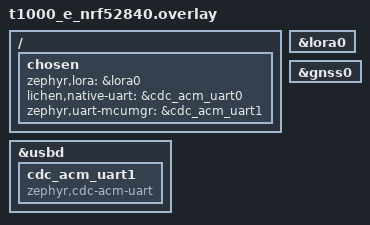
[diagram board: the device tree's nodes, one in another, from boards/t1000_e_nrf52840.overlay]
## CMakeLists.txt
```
# SPDX-License-Identifier: GPL-3.0-or-later
# SPDX-FileCopyrightText: The contributors to the LICHEN project

cmake_minimum_required(VERSION 3.20.0)
include(${CMAKE_CURRENT_LIST_DIR}/../../cmake/lichen_build_epoch.cmake)
lichen_configure_time_build_epoch()
find_package(Zephyr REQUIRED HINTS $ENV{ZEPHYR_BASE})
project(lichen_puck)

target_sources(app PRIVATE src/main.c src/puck_location.c)
target_include_directories(app PRIVATE
  ${CMAKE_CURRENT_SOURCE_DIR}/../../lib/native/include)

zephyr_linker_sources(DATA_SECTIONS sections-ram.ld)
zephyr_iterable_section(
  NAME coap_resource_lichen_coap
  GROUP DATA_REGION ${XIP_ALIGN_WITH_INPUT}
  SUBALIGN CONFIG_LINKER_ITERABLE_SUBALIGN)
# Server section owned exclusively by subsys/lichen/coap/CMakeLists.txt
# under CONFIG_LICHEN_COAP_SERVER_STANDALONE (mutually exclusive with
# modular LICHEN_COAP_CONFIG used by puck/gateway per Kconfig and
# AGENTS.md init graph). Avoids duplication/symbol conflicts from
# worker3 merge.
```

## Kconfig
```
mainmenu "LICHEN Puck"

config LICHEN_PUCK_BEACON_INTERVAL_MS
	int "Beacon TX interval (ms)"
	default 60000
	help
	  How often the puck transmits a bare LICHEN announce beacon.
	  60 s is appropriate for field use; reduce to 5 s for bench testing.

source "Kconfig.zephyr"
```

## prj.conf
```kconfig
# LICHEN puck — field device Kconfig
# Full mesh stack: LoRa radio, IPv6, UDP, CoAP

# LoRa radio (driver selected per-board: LORA_SX12XX or LORA_STM32WL_SUBGHZ_RADIO)
CONFIG_LORA=y

# Networking (disable 802.15.4 L2 — we drive the radio directly)
CONFIG_NET_L2_CUSTOM_IEEE802154=n
CONFIG_NETWORKING=y
CONFIG_NET_IPV6=y
CONFIG_NET_UDP=y
CONFIG_NET_SOCKETS=y

# Application protocols
CONFIG_COAP=y

# LICHEN board capability HAL
CONFIG_LICHEN=y
CONFIG_LICHEN_HAL=y

# RNG (needed for nonces, OSCORE)
CONFIG_ENTROPY_GENERATOR=y
CONFIG_CRC=y

# Stack sizes — LoRa + IPv6 + CoAP need generous stacks.
# Any thread that can originate an L2 TX runs SCHC compression + Monocypher
# Ed25519 signing (2-6 KB of stack) via lichen_link_tx: the zephyr coap_client
# thread (1 KB default — overflowed and wedged both nRF boards at the first
# CoAP send, bd r002) and the system workqueue (ND/DAD-originated sends).
CONFIG_MAIN_STACK_SIZE=4096
CONFIG_SYSTEM_WORKQUEUE_STACK_SIZE=4096
CONFIG_COAP_CLIENT_STACK_SIZE=8192
CONFIG_NET_TX_STACK_SIZE=8192

# Block-wise transfers sized so each block response fits the L2 MTU; must
# match the 128-byte blocks the gateway serves for large resources.
CONFIG_COAP_CLIENT_BLOCK_SIZE=128

# CON retransmit timeout must exceed the real link RTT or the retransmit
# grabs the half-duplex modem exactly when the response is arriving and
# jams it. Worst case at SF10: ~1 s RX window + 0.8 s request airtime +
# ~1 s gateway window + 1.6 s max response airtime ≈ 4.4 s.
# LICHEN uses 15s (matching LICHEN_ACK_TIMEOUT in Python/Rust) to avoid
# premature retransmits over high-latency LoRa links.
CONFIG_COAP_INIT_ACK_TIMEOUT_MS=15000
# RX side of the same: Ed25519 verify + SCHC decompress run on the LoRa L2
# RX thread; IPv6/UDP delivery runs on the net RX thread.
CONFIG_LICHEN_LORA_L2_RX_STACK_SIZE=8192
CONFIG_NET_RX_STACK_SIZE=4096

# Short RX window for TX responsiveness (every TX waits out the in-flight
# window via the modem mutex). Frames that straddle the boundary are safe:
# the drivers hold the window open on preamble/header detection instead of
# aborting mid-reception.
CONFIG_LICHEN_LORA_L2_RX_TIMEOUT_MS=1000

# MbedTLS disabled — OSCORE crypto is provided by the LICHEN crypto layer
CONFIG_MBEDTLS=n

# Safety (spec appendix-c-safety)
CONFIG_STACK_CANARIES=y
CONFIG_STACK_SENTINEL=y
CONFIG_ASSERT=y
CONFIG_ASSERT_VERBOSE=y

# Logging
CONFIG_LOG=y
CONFIG_LOG_DEFAULT_LEVEL=3

# Hardware watchdog — resilience against radio-driver lockups (see main.c).
CONFIG_WATCHDOG=y
```

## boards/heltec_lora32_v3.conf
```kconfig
# Heltec LoRa32 v3 board config — USB CDC-ACM + SLIP
# ESP32-S3 uses Zephyr's USB device stack next (UDC)

CONFIG_USB_DEVICE_STACK_NEXT=y
CONFIG_UDC_ESP32SX=y
CONFIG_USBD_CDC_ACM_CLASS=y

CONFIG_SLIP=y
CONFIG_NET_L2_SLIP=y
CONFIG_UART_LINE_CTRL=y
CONFIG_NET_BUF_DATA_SIZE=128
```

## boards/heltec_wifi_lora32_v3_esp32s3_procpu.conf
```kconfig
# SPDX-License-Identifier: GPL-3.0-or-later
# SPDX-FileCopyrightText: The contributors to the LICHEN project
#
# Heltec WiFi LoRa 32 V3 puck config — ESP32-S3 + SX1262.
CONFIG_LORA_SX126X=y
CONFIG_LICHEN_HAS_LORA=y
CONFIG_LICHEN_RADIO_MODEL_SX126X=y
CONFIG_LICHEN_COAP=y
CONFIG_LICHEN_LORA_L2=y
CONFIG_LICHEN_L2=y
# lichen_coap_request() k_malloc()s per-request state.
CONFIG_HEAP_MEM_POOL_SIZE=4096
# 5 s beacon for bench testing (default 60 s) — matches the nRF pucks.
CONFIG_LICHEN_PUCK_BEACON_INTERVAL_MS=5000

# L2 + CoAP path (board-level addition to prj.conf). Radio arbitration by LICHEN_L2 mutex + TDMA per spec/02a-coordinated-capacity.md §2a.2;
# TINYCRYPT auto-pulled via LICHEN_L2 select.
# Battery support for real hardware test (N30 1100mAh) — voltage-divider
# on GPIO1/ADC1_CH0 with GPIO37 control pin (see board DTS + Meshtastic).
CONFIG_LICHEN_HAS_BATTERY=y
CONFIG_SENSOR=y
CONFIG_ADC=y
CONFIG_LICHEN_L2_DEV_PROVISIONING=y
CONFIG_LICHEN_L2_DEV_PEER_EUI64="7a7ff09dc86c2c10,ee452f74419cf281"
```

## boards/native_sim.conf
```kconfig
CONFIG_LORA_LOOPBACK=y
CONFIG_LICHEN_HAS_LORA=y
CONFIG_LICHEN_RADIO_MODEL_LOOPBACK=y
CONFIG_LICHEN_COAP=y
CONFIG_HEAP_MEM_POOL_SIZE=2048
CONFIG_NET_TC_TX_COUNT=1
CONFIG_NET_TC_THREAD_PREEMPTIVE=y
CONFIG_LICHEN_L2_DEV_PROVISIONING=y
CONFIG_LICHEN_L2_DEV_PEER_EUI64="ee452f74419cf281"
```

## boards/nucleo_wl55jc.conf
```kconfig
# Nucleo-WL55JC (STM32WL55) — built-in Sub-GHz radio, no USB peripheral.
# Memory targets: <50KB RAM, <220KB flash (sw3).

# STM32WL uses the built-in SubGHz radio driver (auto-selected from DTS).
# Explicitly enable it; the SX12xx external driver is not present on this board.
CONFIG_SPI=y
CONFIG_LORA_STM32WL_SUBGHZ_RADIO=y
CONFIG_LICHEN_HAS_LORA=y
CONFIG_LICHEN_COAP=y
CONFIG_IWDG_STM32_INITIAL_TIMEOUT=4000

# No USB hardware on STM32WL55 → no CDC-ACM, no USB stack.
CONFIG_USB_DEVICE_STACK=n
CONFIG_USB_DEVICE_STACK_NEXT=n

# Reduce network buffer counts to fit in 64KB SRAM.
CONFIG_NET_PKT_RX_COUNT=4
CONFIG_NET_PKT_TX_COUNT=4
CONFIG_NET_BUF_RX_COUNT=8
CONFIG_NET_BUF_TX_COUNT=8
CONFIG_NET_BUF_DATA_SIZE=128
CONFIG_NET_IPV6_MAX_NEIGHBORS=4
CONFIG_NET_MAX_CONTEXTS=4

# Reduce thread stack sizes
CONFIG_MAIN_STACK_SIZE=2048
CONFIG_SYSTEM_WORKQUEUE_STACK_SIZE=1024

# Minimal logging (level 1 = errors only) to reduce RAM and flash
CONFIG_LOG_DEFAULT_LEVEL=1
```

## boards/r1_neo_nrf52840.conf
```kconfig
# Muzi Works R1 Neo puck config - nRF52840 + SX1262

CONFIG_LORA_SX126X=y
CONFIG_LICHEN_HAS_LORA=y
CONFIG_LICHEN_RADIO_MODEL_SX126X=y

# LICHEN Native protocol over USB CDC-ACM.
CONFIG_USB_DEVICE_VID=0x239A
CONFIG_USB_DEVICE_PID=0x0029
CONFIG_USB_DEVICE_PRODUCT="LICHEN Puck"
CONFIG_USB_DEVICE_MANUFACTURER="LICHEN"
CONFIG_ZCBOR=y
CONFIG_LICHEN_NATIVE=y
CONFIG_LICHEN_HAS_SERIAL_LOCAL=y

# Board capability boundary for app-facing hardware decisions.
CONFIG_LICHEN_BOARD_NAME="Muzi Works R1 Neo"
CONFIG_LICHEN_HAS_BUTTONS=y
CONFIG_LICHEN_HAS_LEDS=y
CONFIG_LICHEN_UI_PROFILE_TRACKER=y

# R1 Neo battery ADC is modeled in the board DTS as a voltage-divider sensor.
CONFIG_SENSOR=y
CONFIG_LICHEN_HAS_BATTERY=y

# Hardware present but intentionally disabled until validated or modeled.
CONFIG_LICHEN_HAS_DISPLAY=n
CONFIG_LICHEN_HAS_GNSS=n
CONFIG_LICHEN_HAS_PMIC=n
CONFIG_LICHEN_HAS_EXTERNAL_FLASH=n
```

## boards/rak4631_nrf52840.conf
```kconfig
# RAK4631 board config — USB CDC-ACM + SLIP for border-router tethering

CONFIG_LICHEN_BOARD_NAME="RAKwireless RAK4631"

# USB device stack (nRF52840 native USB)
CONFIG_USB_DEVICE_STACK=y
CONFIG_USB_DEVICE_VID=0x239A
CONFIG_USB_DEVICE_PID=0x0029
CONFIG_USB_DEVICE_PRODUCT="LICHEN Puck"
CONFIG_USB_DEVICE_MANUFACTURER="LICHEN"
CONFIG_USB_CDC_ACM=y
CONFIG_UART_LINE_CTRL=y

# LICHEN LCI SLIP over the CDC-ACM virtual serial port
CONFIG_NET_DRIVERS=y
CONFIG_NET_L2_DUMMY=y
CONFIG_SLIP=n
CONFIG_LICHEN_SLIP_TRANSPORT=y
CONFIG_SLIP_TRANSPORT_USB_CDC_ACM=y

# Networking (already in prj.conf; repeated here to be explicit)
CONFIG_NET_IPV6=y

# Larger slip receive buffer (MTU 1280 for IPv6 minimum)
CONFIG_NET_BUF_DATA_SIZE=128

CONFIG_SPI=y
CONFIG_LORA_SX126X=y
CONFIG_LICHEN_HAS_LORA=y
CONFIG_LICHEN_RADIO_MODEL_SX126X=y
CONFIG_LICHEN_HAS_SERIAL_LOCAL=y

# L2/CoAP mode: with a LoRa radio present, LICHEN_LORA_L2/LICHEN_L2 default
# on and main.c compiles the CoAP client path, so LICHEN_COAP must be
# enabled (same as T-Echo). lichen_coap_request() k_malloc()s per-request.
CONFIG_LICHEN_COAP=y
CONFIG_HEAP_MEM_POOL_SIZE=2048

# L2/CoAP dev provisioning to reach CoAP GET /status (fixes startup stall)
# Matches T-Echo/t1000e pattern for bench interoperability with Heltec gateway.

CONFIG_LICHEN_L2_DEV_PROVISIONING=y
CONFIG_LICHEN_L2_DEV_PEER_EUI64="ee452f74419cf281"
```

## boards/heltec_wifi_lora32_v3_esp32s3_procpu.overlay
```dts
/*
 * Heltec WiFi LoRa 32 V3 puck overlay — ESP32-S3 + SX1262
 *
 * The out-of-tree board DTS (lichen/boards/heltec/heltec_wifi_lora32_v3/)
 * already defines lora0 on spi2.  This overlay wires it into the Zephyr
 * LoRa subsystem via the chosen binding.
 */

/ {
	chosen {
		zephyr,lora = &lora0;
	};
};
```

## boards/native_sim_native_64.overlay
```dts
/ {
	chosen {
		zephyr,lora = &lora_loopback;
	};

	lora_loopback: lora {
		compatible = "lichen,lora-loopback";
		status = "okay";
	};
};
```

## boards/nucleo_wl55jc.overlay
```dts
/*
 * Nucleo-WL55JC — STM32WL55 with built-in Sub-GHz radio.
 *
 * The board DTS already configures the Sub-GHz radio (&lora / radio@0 inside
 * &subghzspi) with GPIOs, TCXO timing, and the RFO-HP output. This overlay
 * just points the Zephyr LoRa and SLIP aliases at those nodes.
 *
 * SLIP is tunnelled over LPUART1 (PA2/PA3 → ST-LINK virtual COM port).
 */

/ {
	chosen {
		zephyr,lora      = &lora;
		zephyr,uart-pipe = &lpuart1;
	};
};
```

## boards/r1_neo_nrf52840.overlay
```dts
/*
 * Muzi Works R1 Neo puck overlay - enables SX1262 for the puck app.
 */

/ {
	chosen {
		zephyr,lora = &lora0;
		lichen,native-uart = &cdc_acm_uart0;
	};
};

&lora0 {
	status = "okay";
};
```

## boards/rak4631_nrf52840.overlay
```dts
/*
 * RAK4631 — nRF52840 + SX1262
 *
 * The upstream board definition declares the SX1262 as node label &lora on
 * SPI1 and aliases it as lora0.  This overlay enables the node; runtime RF
 * parameters are set through lora_config().
 */

/ {
	chosen {
		zephyr,lora      = &lora;
		lichen,slip-uart = &cdc_acm_uart0;
	};
};

/* CDC-ACM virtual UART — the host sees this as a /dev/ttyACMx port.
 * The SLIP driver uses it as its serial backend. */
&zephyr_udc0 {
	cdc_acm_uart0: cdc_acm_uart0 {
		compatible = "zephyr,cdc-acm-uart";
	};
};

&lora {
	status = "okay";
};
```

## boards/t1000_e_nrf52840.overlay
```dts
/ {
	chosen {
		zephyr,lora        = &lora0;
		lichen,native-uart = &cdc_acm_uart0;
		zephyr,uart-mcumgr = &cdc_acm_uart1;
	};
};

&lora0  { status = "okay"; };
&gnss0  { status = "okay"; };

/* Second CDC-ACM instance for SMP image management (mcumgr CLI). */
&usbd {
	cdc_acm_uart1: cdc_acm_uart1 {
		compatible = "zephyr,cdc-acm-uart";
	};
};
```

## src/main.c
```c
/* SPDX-License-Identifier: GPL-3.0-or-later */
/* SPDX-FileCopyrightText: The contributors to the LICHEN project */

#include <errno.h>
#include <string.h>

#include <zephyr/device.h>
#include <zephyr/drivers/lora.h>
#include <zephyr/drivers/watchdog.h>
#include <zephyr/kernel.h>
#include <zephyr/pm/device.h>
#include <zephyr/logging/log.h>
#if IS_ENABLED(CONFIG_USB_DEVICE_STACK)
#include <zephyr/usb/usb_device.h>
#endif

#include <lichen/hal.h>

#if IS_ENABLED(CONFIG_LICHEN_NATIVE)
#include <lichen/native.h>
#endif

#include "puck_location.h"

#if IS_ENABLED(CONFIG_LICHEN_L2)
#include <zephyr/net/net_if.h>
#include <zephyr/net/socket.h>
#include <lichen/coap_client.h>
#if IS_ENABLED(CONFIG_LICHEN_COAP_SERVER_STANDALONE)
#include <lichen/coap_server.h>
#endif
#include "lichen_l2.h"
#include "ipv6_addr.h"
#endif

/* Stall-marker uses the nRF GPREGRET2 retention register (nRF boards only). */
#if defined(CONFIG_SOC_FAMILY_NORDIC_NRF)
#include <nrfx_power.h>
#define STALL_MARKER_HAVE 1
#endif

LOG_MODULE_REGISTER(lichen_puck, LOG_LEVEL_INF);

#if IS_ENABLED(CONFIG_LICHEN_L2) && IS_ENABLED(CONFIG_STATS)
#include <zephyr/stats/stats.h>

/* CoAP round-trip counters exported as the "coap" stats group. */
STATS_SECT_START(lichen_coap_stats)
STATS_SECT_ENTRY32(sent)
STATS_SECT_ENTRY32(ok)
STATS_SECT_ENTRY32(err)
STATS_SECT_END;

STATS_NAME_START(lichen_coap_stats)
STATS_NAME(lichen_coap_stats, sent)
STATS_NAME(lichen_coap_stats, ok)
STATS_NAME(lichen_coap_stats, err)
STATS_NAME_END(lichen_coap_stats);

STATS_SECT_DECL(lichen_coap_stats) lichen_coap_stats;
#define COAP_STAT_INC(field) STATS_INC(lichen_coap_stats, field)
#else
#define COAP_STAT_INC(field) do { } while (0)
#endif

/* LoRa parameters per LICHEN spec: SF10 / 125 kHz / CR4-5 @ 915 MHz (US915). */
#define LORA_FREQ_HZ       915000000U
#define LORA_MAX_FRAME     255
#define BEACON_INTERVAL_MS CONFIG_LICHEN_PUCK_BEACON_INTERVAL_MS

/*
 * Unsigned LICHEN announce frame.
 *   [0] length = 4   (bytes following the length field)
 *   [1] llsec  = 0x00  (AddrMode=0, no sig, no enc)
 *   [2] epoch  = 0
 *   [3] seqhi  = 0
 *   [4] seqlo  = incremented on each TX
 */
#define BEACON_HDR_LEN 5
static uint8_t s_beacon[BEACON_HDR_LEN];
static uint8_t s_seqnum;
static uint8_t s_epoch;

#if IS_ENABLED(CONFIG_LICHEN_NATIVE)
/* Placeholder IID — in production derive from nRF52840 FICR. */
static const uint8_t s_iid[8] = { 0x00, 0x11, 0x22, 0x33, 0x44, 0x55, 0x66, 0x77 };

/* Radio stats forwarded to native protocol */
static struct ln_radio_stats s_radio_stats;

#endif

/* --------------------------------------------------------------------------
 * GNSS callback (called from GNSS driver context)
 * -------------------------------------------------------------------------- */

#if defined(LICHEN_HAL_GNSS_DEVICE)
#include <zephyr/drivers/gnss.h>

static void on_gnss_data(const struct device *dev, const struct gnss_data *data)
{
	lichen_puck_location_gnss_callback_for_test(dev, data);
}

GNSS_DATA_CALLBACK_DEFINE(LICHEN_HAL_GNSS_DEVICE, on_gnss_data);
#endif

/* --------------------------------------------------------------------------
 * LICHEN Native incoming message handler
 * -------------------------------------------------------------------------- */

#if IS_ENABLED(CONFIG_LICHEN_NATIVE)
static void on_native_rx(uint8_t msg_type, const uint8_t *buf, size_t len)
{
	/*
	 * lichen_native_handle_rx handles hello and log_subscribe internally.
	 * send_message (0x20) → transmit on LoRa.
	 */
	if (msg_type == LN_TYPE_SEND_MESSAGE) {
		/* Minimal: ignore routing, blast the payload over LoRa.
		 * Full implementation would parse dest IID and route. */
		LOG_DBG("host send_message — LoRa TX not yet implemented");
	} else {
		lichen_native_handle_rx(msg_type, buf, len);
	}
}
#endif

/* --------------------------------------------------------------------------
 * LoRa helpers (raw-radio mode only — under CONFIG_LICHEN_L2 the net
 * interface owns the half-duplex radio and these would fight its RX thread)
 * -------------------------------------------------------------------------- */

#if !IS_ENABLED(CONFIG_LICHEN_L2)
static int lora_set_mode(const struct device *dev, bool tx)
{
	struct lora_modem_config cfg = {
		.frequency     = LORA_FREQ_HZ,
		.bandwidth     = BW_125_KHZ,
		.datarate      = SF_10,
		.coding_rate   = CR_4_5,
		.preamble_len  = 8,
		.tx_power      = 14,
		.tx            = tx,
		.public_network = false,
	};
	return lora_config(dev, &cfg);
}
#endif /* !CONFIG_LICHEN_L2 */

/* Main-loop phase marker (retained across watchdog reset — see stall_report).
 *
 * Stored in the GPREGRET2 retention register, NOT RAM: MCUboot runs between the
 * watchdog reset and the app and clobbers .noinit RAM, but leaves GPREGRET2
 * alone. GPREGRET (reg 0) is reserved for the DFU-touch magic. High nibble
 * 0xA0 = valid marker, low nibble = phase. */
enum stall_phase {
	PH_BOOT = 0, PH_RECV, PH_RX_FORWARD, PH_CFG_TX,
	PH_TX, PH_CFG_RX, PH_NODE_INFO, PH_NPHASES,
};

#define STALL_GPREG_MAGIC 0xA0u

static inline void set_phase(enum stall_phase ph)
{
#if defined(STALL_MARKER_HAVE)
	NRF_POWER->GPREGRET2 = STALL_GPREG_MAGIC | ((uint32_t)ph & 0x0Fu);
#else
	ARG_UNUSED(ph);
#endif
}

#if !IS_ENABLED(CONFIG_LICHEN_L2)
static void send_beacon(const struct device *dev)
{
	/* Build beacon header */
	s_beacon[0] = BEACON_HDR_LEN - 1;
	s_beacon[1] = 0x00;  /* LLSec: AddrMode=0, no sig, no enc */
	if (++s_seqnum == 0) {
		s_epoch++;  /* Increment epoch on seqnum wrap */
	}
	s_beacon[2] = s_epoch;   /* epoch */
	s_beacon[3] = 0x00;      /* seqhi */
	s_beacon[4] = s_seqnum;  /* seqlo */

	set_phase(PH_CFG_TX);
	if (lora_set_mode(dev, true) < 0) {
		LOG_ERR("TX config failed");
		return;
	}
	set_phase(PH_TX);
	int ret = lora_send(dev, s_beacon, sizeof(s_beacon));
	if (ret < 0) {
		LOG_ERR("beacon TX failed: %d", ret);
	} else {
		LOG_INF("beacon seq=%u", s_seqnum);
#if IS_ENABLED(CONFIG_LICHEN_NATIVE)
		s_radio_stats.tx_pkts++;
#endif
	}
	set_phase(PH_CFG_RX);
	lora_set_mode(dev, false);
}
#endif /* !CONFIG_LICHEN_L2 */

#if IS_ENABLED(CONFIG_LICHEN_L2)
static void on_coap_response(void *user_data, int status, uint8_t code,
			     const uint8_t *payload, size_t payload_len)
{
	ARG_UNUSED(user_data);

	if (status != LICHEN_COAP_OK) {
		LOG_WRN("CoAP response error: %d", status);
		COAP_STAT_INC(err);
		return;
	}
	COAP_STAT_INC(ok);
	LOG_INF("CoAP %u.%02u response, %u B payload",
		code >> 5, code & 0x1F, (unsigned int)payload_len);
	if (payload_len > 0) {
		LOG_HEXDUMP_INF(payload, MIN(payload_len, 64), "payload");
	}
}
#endif /* CONFIG_LICHEN_L2 */

/* --------------------------------------------------------------------------
 * Hardware watchdog — resilience against radio-driver lockups
 *
 * A LoRa TX/RX can wedge the main thread (e.g. a radio SPI transaction that
 * never completes when USB-CDC EasyDMA contends with the SPIM). We can't feed
 * the watchdog straight from the main loop: a normal RX wait blocks up to 5 s,
 * so a main-loop-granular watchdog needs a ~20 s timeout — slow recovery that
 * makes host monitoring painful (long USB drop-outs).
 *
 * Instead we track a "progress" heartbeat that the radio driver bumps from
 * inside its poll loops (via the weak lichen_radio_progress() hook it calls),
 * plus the main loop each iteration. A k_timer feeds the SoC watchdog only
 * while the heartbeat is fresh. Normal multi-second RX/TX waits keep bumping
 * the heartbeat so they don't trip it; a genuine stall stops the bumps and the
 * watchdog resets within a few seconds.
 *
 * The feeder runs from a k_timer (system-clock ISR), NOT a thread: under heavy
 * USB-CDC contention the CDC work queue can starve a cooperative feeder thread,
 * which would withhold the feed and reset the SoC even though main is fine. A
 * timer ISR cannot be starved by threads.
 * -------------------------------------------------------------------------- */

/* WDT_STALL_MS must exceed the longest legitimately-blocking main-loop step
 * that does NOT bump the heartbeat — i.e. the SX126x RX k_poll wait (the LR1110
 * RX/TX poll loops bump continuously). We cap the RX window at RX_WINDOW_MS
 * (< WDT_STALL_MS) so a normal RX never looks like a stall. */
#define WDT_TIMEOUT_MS   4000   /* SoC reset if not fed for this long */
#define WDT_STALL_MS     4000   /* feeder withholds the feed after no progress this long */
#define WDT_FEED_MS      500    /* feeder cadence */
#define RX_WINDOW_MS     2000   /* per-iteration RX listen window */

static const struct device *s_wdt;
static int s_wdt_channel = -1;
static atomic_t s_last_progress_ms;

/* Marks forward progress. Strong definition overriding the radio driver's weak
 * stub, so the driver's poll loops bump this heartbeat too. */
void lichen_radio_progress(void)
{
	atomic_set(&s_last_progress_ms, (atomic_val_t)k_uptime_get());
}

/* Runs in system-clock ISR context — feed only while progress is fresh. */
static void wdt_feed_timer_fn(struct k_timer *t)
{
	ARG_UNUSED(t);
	int64_t age = k_uptime_get() - (int64_t)atomic_get(&s_last_progress_ms);

	if (s_wdt && age < WDT_STALL_MS) {
		wdt_feed(s_wdt, s_wdt_channel);
	}
	/* else: no forward progress → withhold feed → SoC resets */
}

static K_TIMER_DEFINE(s_wdt_timer, wdt_feed_timer_fn, NULL);

static void wdt_init(void)
{
	lichen_radio_progress(); /* seed a fresh heartbeat before arming */

#if !DT_NODE_HAS_STATUS(DT_ALIAS(watchdog0), okay)
	/* No watchdog on this board (e.g. native_sim) */
	LOG_WRN("no watchdog0 alias — running without watchdog");
	return;
#else
	s_wdt = DEVICE_DT_GET(DT_ALIAS(watchdog0));
	if (!device_is_ready(s_wdt)) {
		LOG_WRN("watchdog not ready — running without it");
		s_wdt = NULL;
		return;
	}

	struct wdt_timeout_cfg cfg = {
		.flags   = WDT_FLAG_RESET_SOC,
		.window  = { .min = 0, .max = WDT_TIMEOUT_MS },
		.callback = NULL,
	};

	s_wdt_channel = wdt_install_timeout(s_wdt, &cfg);
	if (s_wdt_channel < 0) {
		LOG_WRN("wdt_install_timeout failed: %d", s_wdt_channel);
		s_wdt = NULL;
		return;
	}

	if (wdt_setup(s_wdt, WDT_OPT_PAUSE_HALTED_BY_DBG) < 0) {
		LOG_WRN("wdt_setup failed");
		s_wdt = NULL;
		return;
	}

	k_timer_start(&s_wdt_timer, K_MSEC(WDT_FEED_MS), K_MSEC(WDT_FEED_MS));
	LOG_INF("watchdog armed (%d ms, stall %d ms, timer-fed)",
		WDT_TIMEOUT_MS, WDT_STALL_MS);
#endif /* DT_NODE_HAS_STATUS(DT_ALIAS(watchdog0), okay) */
}

static inline void wdt_kick(void)
{
	lichen_radio_progress();
}

/* --------------------------------------------------------------------------
 * Stall marker — retained across a warm (watchdog) reset
 *
 * The heartbeat watchdog resets the SoC when main stalls, but the deferred log
 * that would say *where* is lost in the reset. set_phase() records the current
 * main-loop phase in a .noinit variable (RAM survives a watchdog reset on
 * nRF52); stall_report() prints it on the next boot. (Types/setter are defined
 * earlier, before send_beacon, since it uses them.)
 * -------------------------------------------------------------------------- */

static void stall_report(void)
{
#if defined(STALL_MARKER_HAVE)
	static const char *const names[PH_NPHASES] = {
		"boot", "recv", "rx_forward", "cfg_tx",
		"tx", "cfg_rx", "node_info",
	};
	uint32_t g  = NRF_POWER->GPREGRET2;
	uint32_t rr = NRF_POWER->RESETREAS;

	NRF_POWER->RESETREAS = rr; /* write-1-to-clear so next boot is fresh */

	uint32_t ph = g & 0x0Fu;
	const char *phn = ((g & 0xF0u) == STALL_GPREG_MAGIC) && ph < PH_NPHASES
			  ? names[ph] : "n/a";

	/* RESETREAS: bit1=DOG(watchdog) bit2=SREQ(soft) bit0=pin bit3=lockup */
	LOG_WRN("*** boot: RESETREAS=0x%08x %s GPREGRET2=0x%02x phase=%s ***",
		rr,
		(rr & BIT(1)) ? "WATCHDOG" :
		(rr & BIT(2)) ? "soft" :
		(rr & BIT(3)) ? "LOCKUP" :
		(rr & BIT(0)) ? "pin" : "poweron/other",
		g, phn);
	set_phase(PH_BOOT);
#endif
}

/* --------------------------------------------------------------------------
 * Main
 * -------------------------------------------------------------------------- */

int main(void)
{
	struct lichen_hal_identity identity;
	int ret;

	LOG_INF("LICHEN puck starting");
	stall_report();

#if IS_ENABLED(CONFIG_LICHEN_L2)
	/* Quiesce the radio before USB bring-up. The L2 RX thread polls the
	 * radio over SPI (EasyDMA) continuously from NET_DEVICE_INIT — on
	 * nRF52840 that traffic during USBD enumeration wedges USB into a
	 * permanent -110 descriptor-read loop (both USB stacks, both radios;
	 * bd lora_ipv6_mesh-r002). Brought back up after USB settles below. */
	struct net_if *l2_iface =
		net_if_get_first_by_type(&NET_L2_GET_NAME(lichen_l2));

	if (l2_iface != NULL) {
		net_if_down(l2_iface);
	}
#endif

	/* Enable USB early so CDC-ACM enumerates before peripheral drivers
	 * start — guarantees serial log visibility even if LoRa/GNSS fails. */
#if IS_ENABLED(CONFIG_USB_DEVICE_STACK)
	usb_enable(NULL);
	k_sleep(K_MSEC(200));
#endif

	lichen_hal_identity_get(&identity);

#if !IS_ENABLED(CONFIG_LICHEN_L2)
	const struct device *lora_dev;

	/* LoRa radio (via the board-capability HAL) */
	ret = lichen_hal_lora_device_get(&lora_dev);
	if (ret < 0) {
		LOG_ERR("LoRa radio unavailable: %d", ret);
		return ret;
	}
	if (lora_set_mode(lora_dev, false) < 0) {
		LOG_ERR("LoRa config failed — spinning for serial debug");
		while (1) {
			wdt_kick();
			k_sleep(K_SECONDS(1));
		}
	}
	LOG_INF("LoRa SF10/125kHz/CR4-5 @ %u Hz", LORA_FREQ_HZ);
#endif

	/* GNSS power-on (PM_DEVICE start) */
#if IS_ENABLED(CONFIG_LICHEN_HAS_GNSS)
	const struct device *gnss_dev;

	if (lichen_hal_gnss_device_get(&gnss_dev) == 0) {
		pm_device_action_run(gnss_dev, PM_DEVICE_ACTION_RESUME);
	}
#endif

	/* LICHEN Native over USB CDC-ACM */
#if IS_ENABLED(CONFIG_LICHEN_NATIVE)
	if (lichen_native_init(on_native_rx) == 0) {
		LOG_INF("LICHEN Native ready");
		lichen_native_send_hello();
	}
#endif

	/* Arm the watchdog just before entering the loop: everything above runs
	 * quickly and deterministically; the loop is where a radio call can
	 * wedge. */
	wdt_init();

#if IS_ENABLED(CONFIG_LICHEN_L2)
	/* L2/CoAP mode: the LICHEN net interface owns the radio and delivers
	 * IPv6 both ways; the app talks CoAP to the dev-provisioned peer.
	 * The ~230 B /status payload arrives via CoAP Block2 (RFC 7959) —
	 * the gateway slices it into 64-byte blocks that each fit the L2
	 * MTU, and the CoAP client reassembles. */
	static const char *const req_path[] = { "status", NULL };
	uint8_t peer_eui64[LICHEN_L2_ADDR_LEN];
	uint8_t peer_iid[LICHEN_L2_ADDR_LEN];
	struct sockaddr_in6 peer_addr = {
		.sin6_family = AF_INET6,
		.sin6_port = htons(5683),
	};
	LOG_INF("L2/CoAP mode on %s", identity.board_name);

	if (l2_iface == NULL) {
		LOG_ERR("no LICHEN L2 iface — idling for debug");
		while (1) {
			wdt_kick();
			k_sleep(K_SECONDS(1));
		}
	}

	/* USB settle: the iface (and its radio-polling RX thread) stays down
	 * until enumeration is safely over — see the net_if_down() above. */
	for (int i = 0; i < 10; i++) {
		wdt_kick();
		k_sleep(K_SECONDS(1));
	}
	net_if_up(l2_iface);
	k_sleep(K_MSEC(500));

	/* Provision AFTER net_if_up: the enable path re-initializes the link
	 * context, which would wipe an earlier-loaded key. */
#if IS_ENABLED(CONFIG_LICHEN_L2_DEV_PROVISIONING)
	ret = -EAGAIN;
	for (int i = 0; i < 50 && ret == -EAGAIN; i++) {
		ret = lichen_l2_dev_provision(peer_eui64);
		if (ret == -EAGAIN) {
			wdt_kick();
			k_sleep(K_MSEC(100));
		}
	}
#else
	/* No provisioning path yet besides the dev one: without a signing key
	 * and a peer, nothing can authenticate. Stay up (USB/native alive)
	 * but radio-idle. */
	ret = -ENOTSUP;
#endif
	if (ret != 0) {
		LOG_ERR("L2 provisioning unavailable (%d) — idling", ret);
		while (1) {
			wdt_kick();
			k_sleep(K_SECONDS(1));
		}
	}

	/* Publish self identity (the "identity canary") so /config/identity,
	 * MeshCore, and logs confirm successful L2 key + app identity setup.
	 * Fixes missing canary in nRF/ESP puck L2 startup. */
	ret = lichen_l2_publish_app_identity("puck", identity.board_name);
	if (ret < 0) {
		LOG_WRN("app identity publish failed (%d)", ret);
	} else {
		LOG_INF("OK: local node identity at startup");
	}

	lichen_eui64_to_iid(peer_eui64, peer_iid);
	lichen_make_link_local(peer_iid,
			       (struct in6_addr *)&peer_addr.sin6_addr);
	peer_addr.sin6_scope_id = net_if_get_by_iface(l2_iface);

	ret = lichen_coap_client_init();
	if (ret != 0) {
		LOG_ERR("CoAP client init failed: %d", ret);
	}

#if IS_ENABLED(CONFIG_LICHEN_COAP_SERVER_STANDALONE)
	ret = lichen_coap_server_init(NULL);
	if (ret != 0) {
		LOG_ERR("CoAP server init failed: %d", ret);
	}
#endif

#if IS_ENABLED(CONFIG_LICHEN_L2) && IS_ENABLED(CONFIG_STATS)
	(void)STATS_INIT_AND_REG(lichen_coap_stats, STATS_SIZE_32, "coap");
#endif

	while (1) {
		set_phase(PH_TX);
		ret = lichen_coap_get(&peer_addr, req_path,
				      on_coap_response, NULL);
		if (ret != 0) {
			LOG_WRN("CoAP GET send failed: %d", ret);
		} else {
			COAP_STAT_INC(sent);
			LOG_INF("CoAP GET /status sent");
		}
		set_phase(PH_RECV);
		for (int i = 0; i < 15; i++) {
			wdt_kick();
			k_sleep(K_SECONDS(1));
		}
	}
#else /* !CONFIG_LICHEN_L2 — raw-radio beacon mode */
	/* Main loop: RX with 5s timeout, beacon every 60s. */
	uint8_t buf[LORA_MAX_FRAME];
	int16_t rssi;
	int8_t  snr;
	int64_t last_tx_ms  = -(int64_t)BEACON_INTERVAL_MS;
#if IS_ENABLED(CONFIG_LICHEN_NATIVE)
	int64_t last_info_ms = 0;
#endif

	while (1) {
		wdt_kick();

		set_phase(PH_RECV);
		int len = lora_recv(lora_dev, buf, sizeof(buf),
				    K_MSEC(RX_WINDOW_MS), &rssi, &snr);

		if (len > 0) {
			static uint32_t rx_count = 0;
			rx_count++;
			LOG_INF("RX %d B rssi=%d snr=%d pkt#%u [%02x %02x]",
				len, rssi, snr, rx_count,
				buf[0], len > 1 ? buf[1] : 0u);
			LOG_HEXDUMP_DBG(buf, MIN(len, 32), "RX payload");
#if IS_ENABLED(CONFIG_LICHEN_NATIVE)
			s_radio_stats.rx_pkts++;
			/* Forward to connected host.
			 * src_iid is unknown at this layer — send zeros. */
			static const uint8_t unknown_iid[8];
			set_phase(PH_RX_FORWARD);
			lichen_native_send_message_received(unknown_iid,
							    buf, len,
							    rssi, snr);
#endif
		}

		int64_t now = k_uptime_get();

		if (now - last_tx_ms >= BEACON_INTERVAL_MS) {
			send_beacon(lora_dev);
			last_tx_ms = now;
		}

		/* Send node_info every 60s */
#if IS_ENABLED(CONFIG_LICHEN_NATIVE)
		if (now - last_info_ms >= 60000) {
			struct lichen_hal_location_time_snapshot location_time;
			struct ln_gps_info gps;
			const struct ln_gps_info *gps_ptr = NULL;

			set_phase(PH_NODE_INFO);
			if (lichen_hal_location_time_snapshot_get(&location_time) == 0 &&
			    lichen_puck_location_snapshot_to_native_gps(&location_time,
								       &gps)) {
				gps_ptr = &gps;
			}
			lichen_native_send_node_info(
				identity.board_name,
				"lichen-fw-0.1.0",
				identity.zephyr_board,
				(uint64_t)now,
				s_iid,
				gps_ptr,
				&s_radio_stats);
			last_info_ms = now;
		}
#endif
	}
#endif /* CONFIG_LICHEN_L2 */
}
```

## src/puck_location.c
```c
/* SPDX-License-Identifier: GPL-3.0-or-later */
/* SPDX-FileCopyrightText: The contributors to the LICHEN project */

#include "puck_location.h"

#include <errno.h>
#include <stdint.h>
#include <time.h>

#include <zephyr/sys/timeutil.h>

static enum lichen_hal_location_fix_state puck_fix_state_from_gnss(
	enum gnss_fix_status fix_status)
{
	if (fix_status == GNSS_FIX_STATUS_NO_FIX) {
		return LICHEN_HAL_LOCATION_FIX_NO_FIX;
	}

	return LICHEN_HAL_LOCATION_FIX_3D;
}

static bool puck_year_is_leap(uint16_t year)
{
	return (year % 4U) == 0U &&
	       ((year % 100U) != 0U || (year % 400U) == 0U);
}

static uint8_t puck_days_in_month(uint16_t year, uint8_t month)
{
	switch (month) {
	case 1U:
	case 3U:
	case 5U:
	case 7U:
	case 8U:
	case 10U:
	case 12U:
		return 31U;
	case 4U:
	case 6U:
	case 9U:
	case 11U:
		return 30U;
	case 2U:
		return puck_year_is_leap(year) ? 29U : 28U;
	default:
		return 0U;
	}
}

static bool puck_gnss_utc_to_unix(const struct gnss_time *utc,
				  uint64_t *unix_time)
{
	struct tm tm = { 0 };
	int64_t epoch;
	uint16_t year;
	uint8_t days;

	if (utc == NULL || unix_time == NULL ||
	    utc->month < 1U || utc->month > 12U ||
	    utc->hour > 23U || utc->minute > 59U ||
	    utc->millisecond > 59999U) {
		return false;
	}

	year = 2000U + utc->century_year;
	days = puck_days_in_month(year, utc->month);
	if (utc->month_day < 1U || utc->month_day > days) {
		return false;
	}

	tm.tm_year = (int)year - 1900;
	tm.tm_mon = (int)utc->month - 1;
	tm.tm_mday = utc->month_day;
	tm.tm_hour = utc->hour;
	tm.tm_min = utc->minute;
	tm.tm_sec = utc->millisecond / 1000U;

	epoch = timeutil_timegm64(&tm);
	if (epoch <= 0) {
		return false;
	}

	*unix_time = (uint64_t)epoch;
	return true;
}

static void puck_submit_gnss_time(const struct gnss_data *data)
{
	uint64_t unix_time;
	struct lichen_hal_time_sample sample = {
		.source_class = LICHEN_HAL_TIME_SOURCE_GNSS,
		.source_name = "gnss0",
		.unix_time_valid = true,
	};

	if (data->info.fix_status == GNSS_FIX_STATUS_NO_FIX) {
		return;
	}

	if (!puck_gnss_utc_to_unix(&data->utc, &unix_time)) {
		return;
	}

	sample.unix_time = unix_time;
	if (data->info.fix_quality != GNSS_FIX_QUALITY_INVALID) {
		sample.quality_valid = true;
		sample.quality = data->info.fix_quality;
	}

	(void)lichen_hal_time_submit(&sample);
}

int lichen_puck_location_submit_gnss(const struct gnss_data *data)
{
	struct lichen_hal_location_sample sample = {
		.source_class = LICHEN_HAL_LOCATION_SOURCE_ONBOARD_HARDWARE,
		.fix_state = LICHEN_HAL_LOCATION_FIX_NO_FIX,
		.fix_source = LICHEN_HAL_FIX_SOURCE_GNSS,
		.source_name = "gnss0",
	};

	if (data == NULL) {
		return -EINVAL;
	}

	puck_submit_gnss_time(data);

	sample.fix_state = puck_fix_state_from_gnss(data->info.fix_status);
	sample.satellites_valid = true;
	sample.satellites = data->info.satellites_cnt > UINT8_MAX ?
			    UINT8_MAX : (uint8_t)data->info.satellites_cnt;

	if (sample.fix_state != LICHEN_HAL_LOCATION_FIX_NO_FIX) {
		sample.latitude_e7_valid = true;
		sample.latitude_e7 = (int32_t)(data->nav_data.latitude / 100);
		sample.longitude_e7_valid = true;
		sample.longitude_e7 = (int32_t)(data->nav_data.longitude / 100);
		sample.altitude_m_valid = true;
		sample.altitude_m = data->nav_data.altitude / 1000;
		sample.altitude_cm_valid = true;
		sample.altitude_cm = data->nav_data.altitude / 10;
	}

	return lichen_hal_location_submit(&sample);
}

void lichen_puck_location_gnss_callback_for_test(const struct device *dev,
						 const struct gnss_data *data)
{
	ARG_UNUSED(dev);

	(void)lichen_puck_location_submit_gnss(data);
}

bool lichen_puck_location_snapshot_to_native_gps(
	const struct lichen_hal_location_time_snapshot *snapshot,
	struct ln_gps_info *gps)
{
	if (snapshot == NULL || gps == NULL) {
		return false;
	}
	if (!snapshot->latitude_e7_valid || !snapshot->longitude_e7_valid) {
		*gps = (struct ln_gps_info){ 0 };
		return false;
	}

	*gps = (struct ln_gps_info){
		.lat_udeg = snapshot->latitude_e7 / 10,
		.lon_udeg = snapshot->longitude_e7 / 10,
		.alt_cm = snapshot->altitude_cm_valid ?
			  snapshot->altitude_cm :
			  (snapshot->altitude_m_valid ?
			   snapshot->altitude_m * 100 : 0),
		.satellites = snapshot->satellites_valid ?
			      snapshot->satellites : 0,
		.valid = true,
	};

	return true;
}
```

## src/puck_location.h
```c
/* SPDX-License-Identifier: GPL-3.0-or-later */
/* SPDX-FileCopyrightText: The contributors to the LICHEN project */

#ifndef LICHEN_PUCK_LOCATION_H_
#define LICHEN_PUCK_LOCATION_H_

#include <stdbool.h>

#include <zephyr/drivers/gnss.h>

#include <lichen/hal.h>
#include <lichen/native.h>

int lichen_puck_location_submit_gnss(const struct gnss_data *data);
void lichen_puck_location_gnss_callback_for_test(const struct device *dev,
						 const struct gnss_data *data);
bool lichen_puck_location_snapshot_to_native_gps(
	const struct lichen_hal_location_time_snapshot *snapshot,
	struct ln_gps_info *gps);

#endif /* LICHEN_PUCK_LOCATION_H_ */
```
